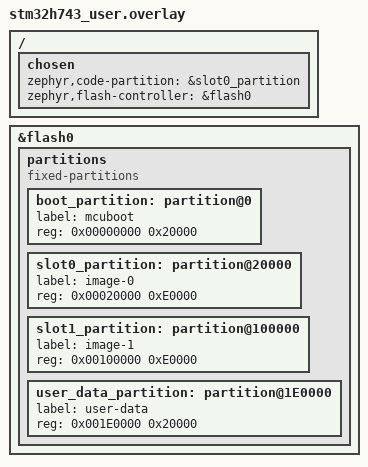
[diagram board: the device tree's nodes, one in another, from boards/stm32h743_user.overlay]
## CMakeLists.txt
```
cmake_minimum_required(VERSION 3.20.0)

# Allow building custom out-of-tree boards stored in ../boards.
list(APPEND BOARD_ROOT ${CMAKE_CURRENT_SOURCE_DIR}/..)

# 获取应用自身的 Git 信息，格式: YYYY-MM-DD_hash
execute_process(
  COMMAND git -C ${CMAKE_CURRENT_SOURCE_DIR} describe --always --dirty --tags
  OUTPUT_VARIABLE APP_GIT_REV
  OUTPUT_STRIP_TRAILING_WHITESPACE
  WORKING_DIRECTORY ${CMAKE_CURRENT_SOURCE_DIR}
  ERROR_QUIET
)
execute_process(
  COMMAND git -C ${CMAKE_CURRENT_SOURCE_DIR} log -1 --format=%cs
  OUTPUT_VARIABLE APP_GIT_DATE
  OUTPUT_STRIP_TRAILING_WHITESPACE
  WORKING_DIRECTORY ${CMAKE_CURRENT_SOURCE_DIR}
  ERROR_QUIET
)

if(APP_GIT_REV AND APP_GIT_DATE)
  set(APP_VERSION "${APP_GIT_DATE}_${APP_GIT_REV}")
else()
  set(APP_VERSION "unknown")
endif()

find_package(Zephyr REQUIRED HINTS $ENV{ZEPHYR_BASE})
project(app95_bootloader)

target_sources(app PRIVATE src/main.c)

# 以宏形式传入 C 代码
target_compile_definitions(app PRIVATE
  APP_VERSION="${APP_VERSION}"
)
```

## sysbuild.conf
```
# Sysbuild 级配置
# 启用 MCUboot 子镜像构建， 让构建系统去拉取编译 MCUboot 源码。
SB_CONFIG_BOOTLOADER_MCUBOOT=y
```

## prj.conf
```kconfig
CONFIG_GPIO=y
CONFIG_LOG=y
CONFIG_LOG_MODE_IMMEDIATE=y
CONFIG_LOG_DEFAULT_LEVEL=3

CONFIG_SERIAL=y
CONFIG_CONSOLE=y
CONFIG_UART_CONSOLE=y

# System tick
CONFIG_SYS_CLOCK_TICKS_PER_SEC=1000

# Flash support
CONFIG_FLASH=y
CONFIG_FLASH_MAP=y
CONFIG_FLASH_PAGE_LAYOUT=y

# CRC32
CONFIG_CRC=y

# Reboot
CONFIG_REBOOT=y

# MCUboot (adds image header for bootloader)
# 让应用镜像带上 MCUboot 兼容的头部和签名
CONFIG_BOOTLOADER_MCUBOOT=y
```

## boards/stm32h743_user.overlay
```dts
/*
 * MCUboot + Dual Slot (A/B) layout on internal flash:
 *   0x00000000 - 0x0001FFFF  MCUboot      (128KB)
 *   0x00020000 - 0x000FFFFF  Slot0 image  (896KB)
 *   0x00100000 - 0x001DFFFF  Slot1 image  (896KB)
 *   0x001E0000 - 0x001FFFFF  User Data    (128KB)
 */

/ {
	chosen {
		zephyr,code-partition = &slot0_partition;
		zephyr,flash-controller = &flash0;
	};
};

&flash0 {
	ranges;
	partitions {
		compatible = "fixed-partitions";
		#address-cells = <1>;
		#size-cells = <1>;

		boot_partition: partition@0 {
			label = "mcuboot";
			reg = <0x00000000 0x20000>;
		};

		slot0_partition: partition@20000 {
			label = "image-0";
			reg = <0x00020000 0xE0000>;
		};

		slot1_partition: partition@100000 {
			label = "image-1";
			reg = <0x00100000 0xE0000>;
		};

		user_data_partition: partition@1E0000 {
			label = "user-data";
			reg = <0x001E0000 0x20000>;
		};
	};
};
```

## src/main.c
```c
#include <zephyr/device.h>
#include <zephyr/drivers/gpio.h>
#include <zephyr/kernel.h>
#include <zephyr/logging/log.h>

LOG_MODULE_REGISTER(app01_led, LOG_LEVEL_INF);

#define LED0_NODE DT_ALIAS(led0)
#define LED1_NODE DT_ALIAS(led1)

#if !DT_NODE_HAS_STATUS(LED0_NODE, okay)
#error "No led0 alias found in device tree"
#endif

static const struct gpio_dt_spec led0 = GPIO_DT_SPEC_GET(LED0_NODE, gpios);
static const struct gpio_dt_spec led1 = GPIO_DT_SPEC_GET(LED1_NODE, gpios);

int main(void)
{
    int ret;

    if(!gpio_is_ready_dt(&led0))
    {
        LOG_ERR("LED0 GPIO device not ready");
        return -1;
    }

    ret = gpio_pin_configure_dt(&led0, GPIO_OUTPUT);
    if(ret < 0)
    {
        LOG_ERR("Failed to configure LED0 pin: %d", ret);
        return ret;
    }

    if(!gpio_is_ready_dt(&led1))
    {
        LOG_ERR("LED1 GPIO device not ready");
        return -1;
    }

    ret = gpio_pin_configure_dt(&led1, GPIO_OUTPUT);
    if(ret < 0)
    {
        LOG_ERR("Failed to configure LED1 pin: %d", ret);
        return ret;
    }

    LOG_INF("Start blinking LED0 on PB3 (IO=0 on, IO=1 off)");
    LOG_INF("Start blinking LED1 on PB4 (IO=0 on, IO=1 off)");

    int count = 0;
    while(1)
    {
        gpio_pin_set_raw(led0.port, led0.pin, 0);
        gpio_pin_set_raw(led0.port, led1.pin, 1);

        count++;
        printk("[%d] Version : %s (uptime=%u ms)\n",
               count, APP_VERSION, k_uptime_get_32());
        k_msleep(500);

        gpio_pin_set_raw(led0.port, led0.pin, 1);
        gpio_pin_set_raw(led1.port, led1.pin, 0);
        k_msleep(500);
    }

    return 0;
}
```
